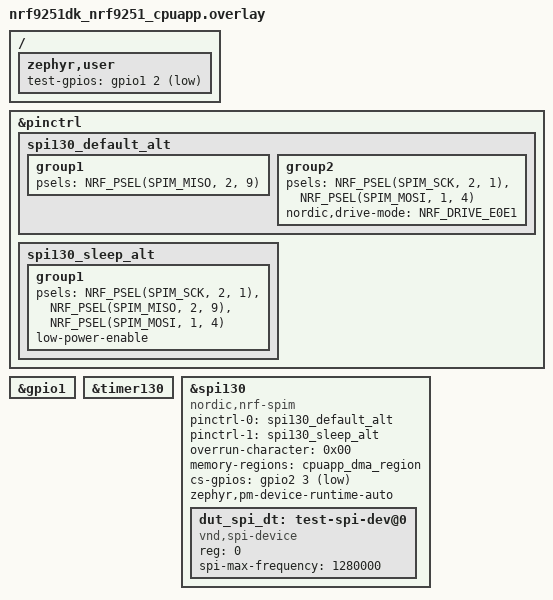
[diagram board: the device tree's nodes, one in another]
/*
 * Copyright (c) 2026 Nordic Semiconductor ASA
 *
 * SPDX-License-Identifier: LicenseRef-Nordic-5-Clause
 */

/* Test requires wire connection:
 *  - SPIM_MOSI with test-gpios -> P1.04 - P1.02.
 */

/ {
	zephyr,user {
		test-gpios = <&gpio1 2 GPIO_ACTIVE_LOW>;
	};
};

&pinctrl {
	spi130_default_alt: spi130_default_alt {
		group1 {
			psels = <NRF_PSEL(SPIM_MISO, 2, 9)>;
		};

		group2 {
			psels = <NRF_PSEL(SPIM_SCK, 2, 1)>,
				<NRF_PSEL(SPIM_MOSI, 1, 4)>;
			nordic,drive-mode = <NRF_DRIVE_E0E1>;
		};
	};

	spi130_sleep_alt: spi130_sleep_alt {
		group1 {
			psels = <NRF_PSEL(SPIM_SCK, 2, 1)>,
				<NRF_PSEL(SPIM_MISO, 2, 9)>,
				<NRF_PSEL(SPIM_MOSI, 1, 4)>;
			low-power-enable;
		};
	};
};

&gpio1 {
	status = "okay";
};

&timer130 {
	status = "okay";
};

&spi130 {
	compatible = "nordic,nrf-spim";
	status = "okay";
	pinctrl-0 = <&spi130_default_alt>;
	pinctrl-1 = <&spi130_sleep_alt>;
	pinctrl-names = "default", "sleep";
	overrun-character = <0x00>;
	memory-regions = <&cpuapp_dma_region>;
	cs-gpios = <&gpio2 3 GPIO_ACTIVE_LOW>;
	zephyr,pm-device-runtime-auto;

	dut_spi_dt: test-spi-dev@0 {
		compatible = "vnd,spi-device";
		reg = <0>;
		spi-max-frequency = <1280000>;
	};
};
